# MCXN236 register map
Vendor: nxp.com; File version: 1.0
CPU: CM33 r2p0, little endian, MPU, FPU, VTOR, 3 interrupt priority bits
Registers are 32-bit, read-write, reset 0x0 unless marked. A register's access mark holds for its fields unless they carry their own. Offsets are from the block's base; [hi:lo] are bit positions; {n}, {i} and the like mark numbered series.

## OSTIMER0 — OSTIMER
Base 0x40049000
0x00 EVTIMERL ro — EVTIMER Low
  [31:0] EVTIMER_COUNT_VALUE
0x04 EVTIMERH ro — EVTIMER High
  [9:0] EVTIMER_COUNT_VALUE
0x08 CAPTURE_L ro — Local Capture Low for CPU
  [31:0] CAPTURE_VALUE — EVTimer Capture Value
0x0C CAPTURE_H ro — Local Capture High for CPU
  [9:0] CAPTURE_VALUE — EVTimer Capture Value
0x10 MATCH_L reset 0xFFFFFFFF — Local Match Low for CPU
  [31:0] MATCH_VALUE — EVTimer Match Value
0x14 MATCH_H reset 0xFFFFFFFF — Local Match High for CPU
  [9:0] MATCH_VALUE — EVTimer Match Value
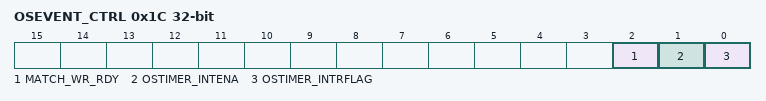
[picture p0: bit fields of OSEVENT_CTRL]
0x1C OSEVENT_CTRL — OSTIMER Control for CPU
  [2] MATCH_WR_RDY — EVTimer Match Write Ready
  [1] OSTIMER_INTENA — Interrupt or Wake-Up Request
    0=INTERRUPTS_BLOCKED; 1=INTERRUPTS_ENABLED
  [0] OSTIMER_INTRFLAG write-1-clears — Interrupt Flag

## LPTMR0 — LPTMR
Base 0x4004A000
Same registers: LPTMR1 0x4004B000
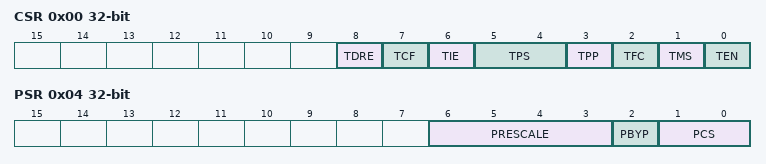
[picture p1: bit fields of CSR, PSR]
0x00 CSR — Control Status
  [8] TDRE — Timer DMA Request Enable
    0=trde0 (Disable); 1=trde1 (Enable)
  [7] TCF write-1-clears — Timer Compare Flag
    0=CNR != (CMR + 1); 1=CNR = (CMR + 1)
  [6] TIE — Timer Interrupt Enable
    0=Disable; 1=Enable
  [5:4] TPS — Timer Pin Select
    {v}=Input {v} (v=0..3)
  [3] TPP — Timer Pin Polarity
    0=Active-high; 1=Active-low
  [2] TFC — Timer Free-Running Counter
    0=Reset if TCF set; 1=Reset on overflow
  [1] TMS — Timer Mode Select
    0=Time Counter mode; 1=Pulse Counter mode
  [0] TEN — Timer Enable
    0=Disable; 1=Enable
0x04 PSR — Prescale and Glitch Filter
  [6:3] PRESCALE — Prescale/Glitch Filter Value
    0=Prescaler divides the prescaler clock by 2; glitch filter does not support this configuration; 1=Prescaler divides the prescaler clock by 4; glitch filter recognizes change on input pin after 2 rising clock edges; 2=Prescaler divides the prescaler clock by 8; glitch filter recognizes change on input pin after 4 rising clock edges; 3=Prescaler divides the prescaler clock by 16; glitch filter recognizes change on input pin after 8 rising clock edges; 4=Prescaler divides the prescaler clock by 32; glitch filter recognizes change on input pin after 16 rising clock edges; 5=Prescaler divides the prescaler clock by 64; glitch filter recognizes change on input pin after 32 rising clock edges; 6=Prescaler divides the prescaler clock by 128; glitch filter recognizes change on input pin after 64 rising clock edges; 7=Prescaler divides the prescaler clock by 256; glitch filter recognizes change on input pin after 128 rising clock edges; 8=Prescaler divides the prescaler clock by 512; glitch filter recognizes change on input pin after 256 rising clock edges; 9=Prescaler divides the prescaler clock by 1024; glitch filter recognizes change on input pin after 512 rising clock edges; 10=Prescaler divides the prescaler clock by 2048; glitch filter recognizes change on input pin after 1024 rising clock edges; 11=Prescaler divides the prescaler clock by 4096; glitch filter recognizes change on input pin after 2048 rising clock edges; 12=Prescaler divides the prescaler clock by 8192; glitch filter recognizes change on input pin after 4096 rising clock edges; 13=Prescaler divides the prescaler clock by 16,384; glitch filter recognizes change on input pin after 8192 rising clock edges; 14=Prescaler divides the prescaler clock by 32,768; glitch filter recognizes change on input pin after 16,384 rising clock edges; 15=Prescaler divides the prescaler clock by 65,536; glitch filter recognizes change on input pin after 32,768 rising clock edges
  [2] PBYP — Prescaler/Glitch Filter Bypass
    0=Prescaler/glitch filter enable; 1=Prescaler/glitch filter bypass
  [1:0] PCS — Prescaler/Glitch Filter Clock Select
    {v}=Clock {v} (v=0..3)
0x08 CMR — Compare
  [31:0] COMPARE — Compare Value
0x0C CNR — Counter
  [31:0] COUNTER — Counter Value
